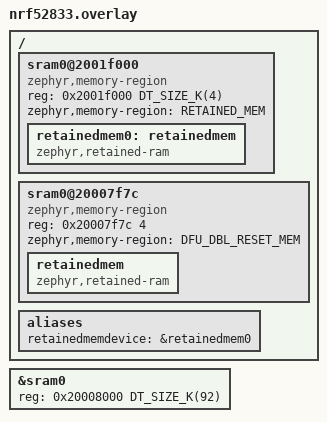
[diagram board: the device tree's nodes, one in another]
/ {
	sram0@2001f000 {
		compatible = "zephyr,memory-region", "mmio-sram";
		reg = <0x2001f000 DT_SIZE_K(4)>;
		zephyr,memory-region = "RETAINED_MEM";
		status = "okay";

		retainedmem0: retainedmem {
			compatible = "zephyr,retained-ram";
			status = "okay";
		};
	};

	sram0@20007f7c {
		compatible = "zephyr,memory-region", "mmio-sram";
		reg = <0x20007f7c 4>;
		zephyr,memory-region = "DFU_DBL_RESET_MEM";
		status = "okay";

		retainedmem {
			compatible = "zephyr,retained-ram";
			status = "okay";
		};
	};

	aliases {
		retainedmemdevice = &retainedmem0;
	};
};

&sram0 {
	/* Start SRAM after DFU_DBL_RESET_MEM (0x20007F7C+4) to prevent BSS overlap,
	 * and end before RETAINED_MEM (0x2001F000) */
	reg = <0x20008000 DT_SIZE_K(92)>;
};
